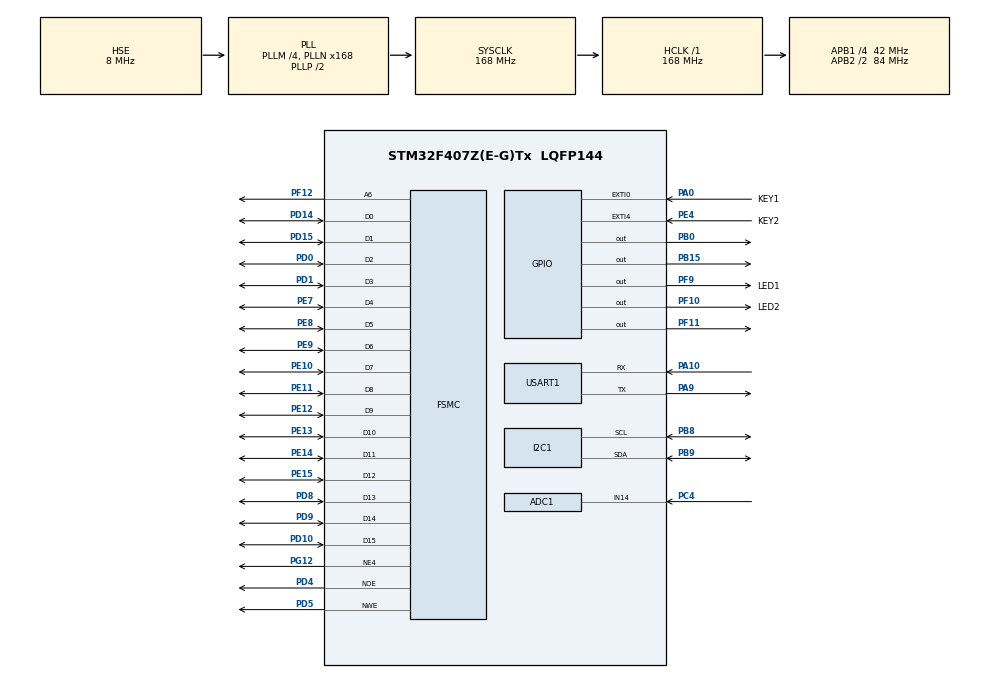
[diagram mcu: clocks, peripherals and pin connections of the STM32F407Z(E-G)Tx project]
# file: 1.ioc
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ADC1.Channel-0\#ChannelRegularConversion=ADC_CHANNEL_14
ADC1.DMAContinuousRequests=ENABLE
ADC1.ExternalTrigConv=ADC_EXTERNALTRIGCONV_T8_TRGO
ADC1.NbrOfConversionFlag=1
ADC1.Rank-0\#ChannelRegularConversion=1
ADC1.SamplingTime-0\#ChannelRegularConversion=ADC_SAMPLETIME_3CYCLES
ADC1.master=1
Dma.ADC1.0.Direction=DMA_PERIPH_TO_MEMORY
Dma.ADC1.0.FIFOMode=DMA_FIFOMODE_DISABLE
Dma.ADC1.0.Instance=DMA2_Stream0
Dma.ADC1.0.MemDataAlignment=DMA_MDATAALIGN_HALFWORD
Dma.ADC1.0.MemInc=DMA_MINC_ENABLE
Dma.ADC1.0.Mode=DMA_CIRCULAR
Dma.ADC1.0.PeriphDataAlignment=DMA_PDATAALIGN_HALFWORD
Dma.ADC1.0.PeriphInc=DMA_PINC_DISABLE
Dma.ADC1.0.Priority=DMA_PRIORITY_VERY_HIGH
Dma.Request0=ADC1
FSMC.BusTurnAroundDuration1=0
FSMC.DataSetupTime1=60
FSMC.ExtendedAddressSetupTime1=9
FSMC.ExtendedBusTurnAroundDuration1=0
FSMC.ExtendedDataSetupTime1=8
FSMC.ExtendedMode1=FSMC_EXTENDED_MODE_ENABLE
Mcu.Family=STM32F4
Mcu.Name=STM32F407Z(E-G)Tx
Mcu.Package=LQFP144
NVIC.DMA2_Stream0_IRQn=true\:0\:0\:false\:false\:true\:false\:true\:true
NVIC.EXTI0_IRQn=true\:3\:3\:true\:false\:true\:true\:true\:true
NVIC.EXTI4_IRQn=true\:3\:3\:true\:false\:true\:true\:true\:true
NVIC.PriorityGroup=NVIC_PRIORITYGROUP_2
NVIC.TIM6_DAC_IRQn=true\:0\:0\:false\:false\:true\:true\:true\:true
NVIC.USART1_IRQn=true\:0\:0\:false\:false\:true\:true\:true\:true
PA0-WKUP.GPIO_Label=KEY1
PA0-WKUP.GPIO_ModeDefaultEXTI=GPIO_MODE_IT_RISING
PA0-WKUP.GPIO_PuPd=GPIO_PULLDOWN
PA0-WKUP.Signal=GPXTI0
PA10.Mode=Asynchronous
PA10.Signal=USART1_RX
PA13.Mode=Serial_Wire
PA13.Signal=SYS_JTMS-SWDIO
PA14.Mode=Serial_Wire
PA14.Signal=SYS_JTCK-SWCLK
PA9.Mode=Asynchronous
PA9.Signal=USART1_TX
PB0.GPIO_PuPd=GPIO_PULLUP
PB0.GPIO_Speed=GPIO_SPEED_FREQ_VERY_HIGH
PB0.Signal=GPIO_Output
PB15.GPIO_Speed=GPIO_SPEED_FREQ_HIGH
PB15.PinState=GPIO_PIN_SET
PB15.Signal=GPIO_Output
PB8.Mode=I2C
PB8.Signal=I2C1_SCL
PB9.Mode=I2C
PB9.Signal=I2C1_SDA
PC4.Signal=ADCx_IN14
PD0.Signal=FSMC_D2_DA2
PD1.Signal=FSMC_D3_DA3
PD10.Signal=FSMC_D15_DA15
PD14.Signal=FSMC_D0_DA0
PD15.Signal=FSMC_D1_DA1
PD4.Signal=FSMC_NOE
PD5.Signal=FSMC_NWE
PD8.Signal=FSMC_D13_DA13
PD9.Signal=FSMC_D14_DA14
PE10.Signal=FSMC_D7_DA7
PE11.Signal=FSMC_D8_DA8
PE12.Signal=FSMC_D9_DA9
PE13.Signal=FSMC_D10_DA10
PE14.Signal=FSMC_D11_DA11
PE15.Signal=FSMC_D12_DA12
PE4.GPIO_Label=KEY2
PE4.GPIO_ModeDefaultEXTI=GPIO_MODE_IT_FALLING
PE4.GPIO_PuPd=GPIO_PULLUP
PE4.Signal=GPXTI4
PE7.Signal=FSMC_D4_DA4
PE8.Signal=FSMC_D5_DA5
PE9.Signal=FSMC_D6_DA6
PF10.GPIO_Label=LED2
PF10.PinState=GPIO_PIN_SET
PF10.Signal=GPIO_Output
PF11.GPIO_PuPd=GPIO_PULLUP
PF11.GPIO_Speed=GPIO_SPEED_FREQ_VERY_HIGH
PF11.Signal=GPIO_Output
PF12.Signal=FSMC_A6
PF9.GPIO_Label=LED1
PF9.PinState=GPIO_PIN_SET
PF9.Signal=GPIO_Output
PG12.Mode=NorPsramChipSelect4_1
PG12.Signal=FSMC_NE4
PH0-OSC_IN.Mode=HSE-External-Oscillator
PH0-OSC_IN.Signal=RCC_OSC_IN
PH1-OSC_OUT.Mode=HSE-External-Oscillator
PH1-OSC_OUT.Signal=RCC_OSC_OUT
ProjectManager.HeapSize=0x2000
ProjectManager.StackSize=0x2000
ProjectManager.TargetToolchain=MDK-ARM V5
RCC.48MHZClocksFreq_Value=84000000
RCC.AHBFreq_Value=168000000
RCC.APB1CLKDivider=RCC_HCLK_DIV4
RCC.APB1Freq_Value=42000000
RCC.APB1TimFreq_Value=84000000
RCC.APB2CLKDivider=RCC_HCLK_DIV2
RCC.APB2Freq_Value=84000000
RCC.APB2TimFreq_Value=168000000
RCC.CortexFreq_Value=168000000
RCC.HCLKFreq_Value=168000000
RCC.HSE_VALUE=8000000
RCC.HSI_VALUE=16000000
RCC.LSE_VALUE=32768
RCC.PLLM=4
RCC.PLLN=168
RCC.PLLSourceVirtual=RCC_PLLSOURCE_HSE
RCC.SYSCLKFreq_VALUE=168000000
RCC.SYSCLKSource=RCC_SYSCLKSOURCE_PLLCLK
RCC.VCOOutputFreq_Value=336000000
SH.ADCx_IN14.0=ADC1_IN14,IN14
SH.FSMC_A6.0=FSMC_A6,A6_1
SH.FSMC_D0_DA0.0=FSMC_D0,16b-d1
SH.FSMC_D10_DA10.0=FSMC_D10,16b-d1
SH.FSMC_D11_DA11.0=FSMC_D11,16b-d1
SH.FSMC_D12_DA12.0=FSMC_D12,16b-d1
SH.FSMC_D13_DA13.0=FSMC_D13,16b-d1
SH.FSMC_D14_DA14.0=FSMC_D14,16b-d1
SH.FSMC_D15_DA15.0=FSMC_D15,16b-d1
SH.FSMC_D1_DA1.0=FSMC_D1,16b-d1
SH.FSMC_D2_DA2.0=FSMC_D2,16b-d1
SH.FSMC_D3_DA3.0=FSMC_D3,16b-d1
SH.FSMC_D4_DA4.0=FSMC_D4,16b-d1
SH.FSMC_D5_DA5.0=FSMC_D5,16b-d1
SH.FSMC_D6_DA6.0=FSMC_D6,16b-d1
SH.FSMC_D7_DA7.0=FSMC_D7,16b-d1
SH.FSMC_D8_DA8.0=FSMC_D8,16b-d1
SH.FSMC_D9_DA9.0=FSMC_D9,16b-d1
SH.FSMC_NOE.0=FSMC_NOE,Lcd1
SH.FSMC_NWE.0=FSMC_NWE,Lcd1
TIM6.AutoReloadPreload=TIM_AUTORELOAD_PRELOAD_ENABLE
TIM6.Period=1000000/200
TIM6.Prescaler=168000000/1000000-1
TIM8.AutoReloadPreload=TIM_AUTORELOAD_PRELOAD_ENABLE
TIM8.Period=50-1
TIM8.Prescaler=168-1
TIM8.TIM_MasterOutputTrigger=TIM_TRGO_UPDATE
USART1.VirtualMode=VM_ASYNC
VP_TIM6_VS_ClockSourceINT.Mode=Enable_Timer
VP_TIM8_VS_ClockSourceINT.Mode=Internal
board=custom

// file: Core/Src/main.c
/* USER CODE BEGIN Header */
/**
  ******************************************************************************
  * @file           : main.c
  * @brief          : Main program body
  ******************************************************************************
  * @attention
  *
  * <h2><center>&copy; Copyright (c) 2021 STMicroelectronics.
  * All rights reserved.</center></h2>
  *
  * This software component is licensed by ST under BSD 3-Clause license,
  * the "License"; You may not use this file except in compliance with the
  * License. You may obtain a copy of the License at:
  *                        opensource.org/licenses/BSD-3-Clause
  *
  ******************************************************************************
  */
/* USER CODE END Header */
#include "main.h"
#include "adc.h"
#include "dma.h"
#include "i2c.h"
#include "tim.h"
#include "usart.h"
#include "gpio.h"
#include "fsmc.h"

/* USER CODE BEGIN Includes */
#include "MyApplication.h"
/* USER CODE END Includes */

void SystemClock_Config(void);

int main(void)
{

  /* MCU Configuration--------------------------------------------------------*/

  /* Reset of all peripherals, Initializes the Flash interface and the Systick. */
  HAL_Init();

  /* Configure the system clock */
  SystemClock_Config();

  /* Initialize all configured peripherals */
  MX_GPIO_Init();
  MX_USART1_UART_Init();
  MX_FSMC_Init();
  MX_DMA_Init();
  MX_TIM6_Init();
  MX_ADC1_Init();
  MX_I2C1_Init();
  MX_TIM8_Init();
  /* USER CODE BEGIN 2 */
  MyInit.Peripheral_Set();
  /* USER CODE END 2 */

  /* Infinite loop */
  /* USER CODE BEGIN WHILE */
  while (1)
  {
    System.Run();
    /* USER CODE END WHILE */

  }
}

void SystemClock_Config(void)
{
  RCC_OscInitTypeDef RCC_OscInitStruct = {0};
  RCC_ClkInitTypeDef RCC_ClkInitStruct = {0};

  /** Configure the main internal regulator output voltage
  */
  __HAL_RCC_PWR_CLK_ENABLE();
  __HAL_PWR_VOLTAGESCALING_CONFIG(PWR_REGULATOR_VOLTAGE_SCALE1);
  /** Initializes the RCC Oscillators according to the specified parameters
  * in the RCC_OscInitTypeDef structure.
  */
  RCC_OscInitStruct.OscillatorType = RCC_OSCILLATORTYPE_HSE;
  RCC_OscInitStruct.HSEState = RCC_HSE_ON;
  RCC_OscInitStruct.PLL.PLLState = RCC_PLL_ON;
  RCC_OscInitStruct.PLL.PLLSource = RCC_PLLSOURCE_HSE;
  RCC_OscInitStruct.PLL.PLLM = 4;
  RCC_OscInitStruct.PLL.PLLN = 168;
  RCC_OscInitStruct.PLL.PLLP = RCC_PLLP_DIV2;
  RCC_OscInitStruct.PLL.PLLQ = 4;
  if (HAL_RCC_OscConfig(&RCC_OscInitStruct) != HAL_OK)
  {
    Error_Handler();
  }
  /** Initializes the CPU, AHB and APB buses clocks
  */
  RCC_ClkInitStruct.ClockType = RCC_CLOCKTYPE_HCLK|RCC_CLOCKTYPE_SYSCLK
                              |RCC_CLOCKTYPE_PCLK1|RCC_CLOCKTYPE_PCLK2;
  RCC_ClkInitStruct.SYSCLKSource = RCC_SYSCLKSOURCE_PLLCLK;
  RCC_ClkInitStruct.AHBCLKDivider = RCC_SYSCLK_DIV1;
  RCC_ClkInitStruct.APB1CLKDivider = RCC_HCLK_DIV4;
  RCC_ClkInitStruct.APB2CLKDivider = RCC_HCLK_DIV2;

  if (HAL_RCC_ClockConfig(&RCC_ClkInitStruct, FLASH_LATENCY_5) != HAL_OK)
  {
    Error_Handler();
  }
}

void Error_Handler(void)
{
  /* USER CODE BEGIN Error_Handler_Debug */
  /* User can add his own implementation to report the HAL error return state */
  System.Error_Handler();
  /* USER CODE END Error_Handler_Debug */
}

#ifdef  USE_FULL_ASSERT
/**
  * @brief  Reports the name of the source file and the source line number
  *         where the assert_param error has occurred.
  * @param  file: pointer to the source file name
  * @param  line: assert_param error line source number
  * @retval None
  */
void assert_failed(uint8_t *file, uint32_t line)
{
  /* USER CODE BEGIN 6 */
  /* User can add his own implementation to report the file name and line number,
     ex: printf("Wrong parameters value: file %s on line %d\r\n", file, line) */
	System.Assert_Failed();
  /* USER CODE END 6 */
}
#endif /* USE_FULL_ASSERT */

/************************ (C) COPYRIGHT STMicroelectronics *****END OF FILE****/
